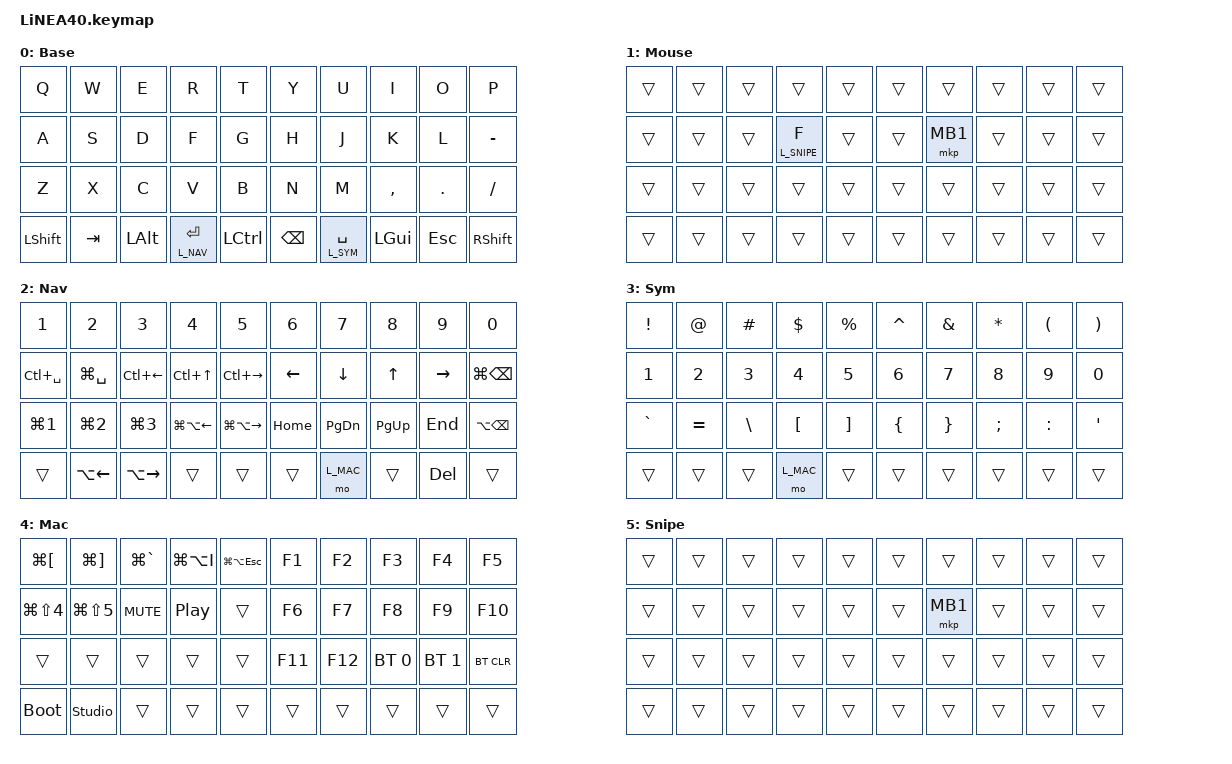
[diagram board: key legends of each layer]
/*
 * LiNEA40 keymap  --  macOS / US layout
 *
 * Modifier layout
 *   Ctrl : left thumb (inner) -- ^P ^N ^H ^K are right-hand letters
 *   Cmd  : right middle finger, bottom row -- its letters (C V X Z A S W Q T F)
 *          are left-hand ones, and Cmd is held rather than tapped, so it can
 *          afford the position Enter gave up. Japanese input taps Enter as often
 *          as Space, and both now sit under a thumb.
 *   Bspc, Ctrl, Cmd, Tab, Alt, Esc and both Shifts are plain &kp. The only two
 *   keys carrying a layer are the ones a thumb rests on: Enter on the left holds
 *   Nav, Space on the right holds Sym, and holding both gives Mac. Whichever
 *   layer the LEFT thumb holds is also the one that makes the trackball scroll,
 *   since that leaves the whole right hand free for the ball.
 *   Bspc gave up its layer deliberately: it is the one key you genuinely want to
 *   hold down, and a layer on the hold made that impossible.
 *
 * Layer numbers 1, 2 and 5 are also referenced by the PMW3610 trackball in
 * LiNEA40_right.overlay (automouse-layer / scroll-layers / snipe-layers).
 * Keep them in sync when renumbering.
 */

#define ZMK_POINTING_DEFAULT_SCRL_VAL 150

#include <behaviors.dtsi>
#include <dt-bindings/zmk/bt.h>
#include <dt-bindings/zmk/input_transform.h>
#include <dt-bindings/zmk/keys.h>
#include <dt-bindings/zmk/pointing.h>
#include <input/processors.dtsi>

/*
 * Layer names are prefixed so the preprocessor cannot rewrite the keymap node
 * names below (a bare `#define MOUSE 1` turns a `MOUSE { }` node into `1 { }`).
 */
#define L_BASE  0
#define L_MOUSE 1   /* automouse-layer -- trackball moves */
#define L_NAV   2   /* scroll-layers   -- trackball scrolls */
#define L_SYM   3
#define L_MAC   4
#define L_SNIPE 5   /* snipe-layers    -- trackball precision */

/*
 * Two layer-taps, tuned differently because their taps fail differently.
 *
 * &lt_tap carries Enter and the F that reaches snipe mode. "balanced" alone
 * breaks a key like that: press it, roll into the next key before releasing it,
 * and decide_balanced() calls that HOLD_INTERRUPT -- the tap never happens and
 * the next key comes off the wrong layer. require-prior-idle-ms settles the key
 * as a tap outright when it follows another keypress closely, so it types while
 * the hands are moving, and its layer is still one hold away once typing pauses.
 * The residue -- hold after a pause and you get the layer, not a repeat -- costs
 * nothing on Enter, which nobody holds.
 *
 * &lt_spc carries Space, and cannot use that trick: require-prior-idle-ms would
 * make Sym unreachable in the middle of typing, which is exactly when a symbol
 * is wanted. "tap-preferred" instead: no other keypress can turn the tap into a
 * hold, only the tapping term can, so a space never goes missing however fast
 * the next letter follows. The cost is that reaching Sym means holding Space for
 * the full term rather than pressing through it.
 */

/* Pointer movement (mouse keys) */

&mmv {
    delay-ms = <20>;
    trigger-period-ms = <5>;
    time-to-max-speed-ms = <100>;
    acceleration-exponent = <2>;
};

/* Pointer scrolling (encoder + mouse keys) */

&msc {
    delay-ms = <3>;
    trigger-period-ms = <3>;
    time-to-max-speed-ms = <100>;
    acceleration-exponent = <0>;
};

/* NAV held -> trackball scrolls instead of moving the pointer. Nav is the left
 * thumb, so the whole right hand stays free for the ball -- which is why this
 * follows whichever layer the left thumb holds. Y is inverted to match macOS
 * natural scrolling. */

&trackball_listener {
    scroller {
        layers = <L_NAV>;
        input-processors =
            <&zip_xy_transform INPUT_TRANSFORM_Y_INVERT>,
            <&zip_xy_to_scroll_mapper>;
    };
};

/ {
    behaviors {
        lt_tap: layer_tap_favouring_the_tap {
            compatible = "zmk,behavior-hold-tap";
            #binding-cells = <2>;
            flavor = "balanced";
            tapping-term-ms = <200>;
            quick-tap-ms = <175>;
            require-prior-idle-ms = <150>;
            bindings = <&mo>, <&kp>;
        };

        lt_spc: layer_tap_on_space {
            compatible = "zmk,behavior-hold-tap";
            #binding-cells = <2>;
            flavor = "tap-preferred";
            tapping-term-ms = <200>;
            quick-tap-ms = <175>;
            bindings = <&mo>, <&kp>;
        };

        kp_enc: sensor_rotate_kp {
            compatible = "zmk,behavior-sensor-rotate-var";
            #sensor-binding-cells = <2>;
            bindings = <&kp>, <&kp>;
        };

        scrl_enc: sensor_rotate_msc {
            compatible = "zmk,behavior-sensor-rotate-var";
            #sensor-binding-cells = <2>;
            bindings = <&msc>, <&msc>;

            tap-ms = <20>;
        };
    };

    /*
     * A key that belongs to a combo has its press captured until the combo
     * resolves or times out, so no key used while typing belongs to one.
     * Space especially: it sat in a combo with Ctrl, its own neighbour under
     * the left thumb at the time, which both delayed every space and turned a
     * slightly wide thumb press into ^Space. Space has since moved to the right
     * thumb, so ^Space is an ordinary two-thumb chord again; the Nav layer keeps
     * a key for it as well.
     *
     * require-prior-idle-ms drops these combos from the candidate list
     * entirely while keys are still flowing, which keeps the capture off the
     * letters they are built from -- "stdio" no longer risks a Delete. Rolling
     * the ball is not a keycode event, so the right-click combo stays live
     * whenever the hand is actually on the ball.
     */
    combos {
        compatible = "zmk,combos";

        del_key {
            bindings = <&kp DEL>;
            key-positions = <7 8>;
            require-prior-idle-ms = <150>;
        };

        /* The one right-click there is. On the Mouse layer a single-key right
         * click has to steal a letter for AUTOMOUSE_TIMEOUT_MS after every ball
         * movement -- it lived on K, and K kept coming out as a context menu.
         * A combo steals nothing: K and L alone type their letters, and pressing
         * them together is a deliberate act a linger window cannot fake. */
        right_click {
            bindings = <&mkp MB2>;
            key-positions = <17 18>;
            require-prior-idle-ms = <150>;
        };
    };

    keymap {
        compatible = "zmk,keymap";

        /*
         * 40 keys. The bottom row carries five per half: the encoder occupies
         * the position between Alt and Enter on the left, and the trackball the
         * one between Space and Cmd on the right. Neither is in the layout.
         *
         *  Q      W      E      R      T                  Y      U      I      O      P
         *  A      S      D      F      G                  H      J      K      L      -
         *  Z      X      C      V      B                  N      M      ,      .      /
         *  Shift  Tab    Alt   (enc) Enter Ctrl   Bspc   Space  (ball)  Cmd    Esc    Shift
         *                            (NAV)                     (SYM)
         *
         * Only the two thumb keys hold layers, which is what lets Nav and Sym put
         * a full ten-key row under the fingers: a thumb hold leaves all ten free,
         * where a layer key held by a finger blocks its own column.
         *
         * Twenty-six letters plus "," and "." fill 28 of the 30 alpha keys, so the
         * right pinky column has exactly two slots for punctuation and there are
         * three candidates. "-" holds one because it types the Japanese long vowel
         * mark, which turns up about as often as a letter, and "/" the other. ";"
         * is the one that loses; it and ":" sit next to each other on the Num
         * layer, a thumb hold plus a key rather than a hold plus Shift as well.
         */
        base_layer {
            display-name = "Base";
            bindings = <
&kp Q        &kp W          &kp E           &kp R        &kp T             &kp Y              &kp U               &kp I        &kp O            &kp P
&kp A        &kp S          &kp D           &kp F        &kp G             &kp H              &kp J               &kp K        &kp L            &kp MINUS
&kp Z        &kp X          &kp C           &kp V        &kp B             &kp N              &kp M               &kp COMMA    &kp DOT          &kp SLASH
&kp LSHFT    &kp TAB        &kp LALT        &lt_tap L_NAV ENTER  &kp LCTRL           &kp BSPC           &lt_spc L_SYM SPACE  &kp LGUI     &kp ESC          &kp RSHFT
            >;

            sensor-bindings = <&scrl_enc SCRL_DOWN SCRL_UP>;
        };

        /*
         * Layer 1 -- entered automatically while the trackball is moving
         * (automouse-layer in LiNEA40_right.overlay), and it lingers for
         * AUTOMOUSE_TIMEOUT_MS after the ball stops. Every key bound here is a
         * letter stolen during that window, so the layer carries exactly one:
         * left click on J, under the index of the hand already on the ball.
         * It used to carry the full five-button cluster across the home row,
         * and K and L kept coming out as a context menu and a browser Back.
         * Right click is the K+L combo, which steals nothing.
         *
         * Hold the left index (F) to slow the ball down; the left hand is idle
         * while the right one is on the ball. It is a hold-tap rather than a
         * plain &mo because of the same linger: a plain &mo would swallow the
         * "f" of a word typed right after nudging the ball.
         */
        mouse_layer {
            display-name = "Mouse";
            bindings = <
&trans     &trans         &trans          &trans           &trans                                  &trans      &trans           &trans              &trans      &trans
&trans     &trans         &trans          &lt_tap L_SNIPE F    &trans                                  &trans      &mkp MB1         &trans              &trans      &trans
&trans     &trans         &trans          &trans           &trans                                  &trans      &trans           &trans              &trans      &trans
&trans     &trans         &trans          &trans           &trans          &trans  &trans          &trans              &trans           &trans
            >;
        };

        /*
         * Layer 2 -- held by the left thumb (Enter). A thumb hold leaves all ten
         * fingers free, so this layer too can carry a full row across the top.
         *
         *  1        2       3       4        5          6     7     8     9      0
         *  Ctrl-Spc Cmd-Spc Ctrl-Lt Ctrl-Up  Ctrl-Rt    Left  Down  Up    Right  Cmd-Bspc
         *  Cmd-1    Cmd-2   Cmd-3   Cmd-Alt-Lt Cmd-Alt-Rt Home PgDn  PgUp  End    Alt-Bspc
         *           Alt-Lt  Alt-Rt                                (MAC)   Del
         *                                                  (encoder: undo/redo)
         *
         * The top row is the digits. Sym carries the shifted forms on its own top
         * row in the same columns, so it is the left thumb for a digit and the
         * right thumb for the symbol above it; Sym keeps a digit copy one row
         * down, so either thumb reaches a number.
         *
         * The arrows sit on h j k l, on the keys and under the fingers Vim uses
         * -- including h as the index stretch. Line and page jumps sit below,
         * the delete family on the right of the bottom two rows.
         *
         * Shift and Cmd stay transparent here: shift-arrow and cmd-shift-arrow
         * have to keep selecting text.
         *
         * What the extra row displaced -- screenshots, DevTools, force quit,
         * browser history, same-app window switching, mute and play -- moved to
         * the Mac layer, whose left hand was empty.
         *
         * Adding Sym on top of this reaches the Mac layer -- both thumbs down.
         */
        nav_layer {
            display-name = "Nav";
            bindings = <
&kp N1       &kp N2         &kp N3          &kp N4               &kp N5              &kp N6             &kp N7               &kp N8       &kp N9           &kp N0
&kp LC(SPACE)&kp LG(SPACE)  &kp LC(LEFT)    &kp LC(UP)   &kp LC(RIGHT)     &kp LEFT           &kp DOWN            &kp UP       &kp RIGHT        &kp LG(BSPC)
&kp LG(N1)   &kp LG(N2)     &kp LG(N3)      &kp LG(LA(LEFT))&kp LG(LA(RIGHT))  &kp HOME           &kp PG_DN           &kp PG_UP    &kp END          &kp LA(BSPC)
&trans       &kp LA(LEFT)   &kp LA(RIGHT)   &trans               &trans              &trans             &mo L_MAC            &trans       &kp DEL          &trans
            >;

            sensor-bindings = <&kp_enc LG(Z) LG(LS(Z))>;
        };

        /*
         * Layer 3 -- held by the right thumb (Space), which leaves every finger
         * free, so the symbols sit in a real shifted-number row across both hands,
         * with the digits they belong to directly underneath, column for column.
         *
         *  !  @  #  $  %      ^  &  *  (  )
         *  1  2  3  4  5      6  7  8  9  0
         *  `  =  \  [  ]      {  }  ;  :  '
         *
         * US layout, so Shift covers what is left over: ~ from `, + from =,
         * | from \, " from ', and on the base layer _ from - and ? from /.
         * The digit row here is a second path to the numbers; the left thumb has
         * them on its own top row.
         *
         * Adding Nav on top of this reaches the Mac layer.
         */
        sym_layer {
            display-name = "Sym";
            bindings = <
&kp EXCL     &kp AT         &kp HASH        &kp DLLR             &kp PRCNT           &kp CARET          &kp AMPS             &kp ASTRK    &kp LPAR         &kp RPAR
&kp N1       &kp N2         &kp N3          &kp N4               &kp N5              &kp N6             &kp N7               &kp N8       &kp N9           &kp N0
&kp GRAVE    &kp EQUAL      &kp BSLH        &kp LBKT     &kp RBKT          &kp LBRC           &kp RBRC            &kp SEMI     &kp COLON        &kp SQT
&trans       &trans         &trans          &mo L_MAC            &trans              &trans             &trans               &trans       &trans           &trans
            >;

            sensor-bindings = <&kp_enc C_VOL_DN C_VOL_UP>;
        };

        /*
         * Layer 4 -- reached by holding both thumb keys, Space and Enter, in
         * either order. Holding thumbs leaves every finger free, so both halves
         * are usable: F-keys and pairing on the right, and on the left the
         * occasional app shortcuts that the Nav symbol row pushed out of Nav.
         * All of it is rare enough to live behind a two-key hold.
         */
        mac_layer {
            display-name = "Mac";
            bindings = <
&kp LG(LBKT) &kp LG(RBKT)   &kp LG(GRAVE)   &kp LG(LA(I))&kp LG(LA(ESC))   &kp F1             &kp F2              &kp F3       &kp F4           &kp F5
&kp LG(LS(N4))&kp LG(LS(N5)) &kp C_MUTE      &kp C_PP     &trans            &kp F6             &kp F7              &kp F8       &kp F9           &kp F10
&trans       &trans         &trans          &trans       &trans            &kp F11            &kp F12             &bt BT_SEL 0 &bt BT_SEL 1     &bt BT_CLR
&bootloader  &studio_unlock &trans          &trans       &trans            &trans             &trans              &trans       &trans           &trans
            >;

            sensor-bindings = <&kp_enc C_VOL_DN C_VOL_UP>;
        };

        /*
         * Layer 5 -- trackball precision mode (snipe-layers), held from the
         * Mouse layer. It repeats that layer's left click rather than falling
         * through to the letter underneath: the driver only activates the
         * automouse layer while input_mode is MOVE (pmw3610.c), so in snipe
         * mode layer 1 is gone and its click with it -- which would leave the
         * ball able to aim precisely at something it cannot click. The K+L
         * right-click combo is position-based and works here unaided.
         */
        snipe_layer {
            display-name = "Snipe";
            bindings = <
&trans     &trans         &trans          &trans       &trans                                      &trans      &trans           &trans              &trans      &trans
&trans     &trans         &trans          &trans       &trans                                      &trans      &mkp MB1         &trans              &trans      &trans
&trans     &trans         &trans          &trans       &trans                                      &trans      &trans           &trans              &trans      &trans
&trans     &trans         &trans          &trans       &trans          &trans      &trans          &trans              &trans           &trans
            >;
        };
    };
};
